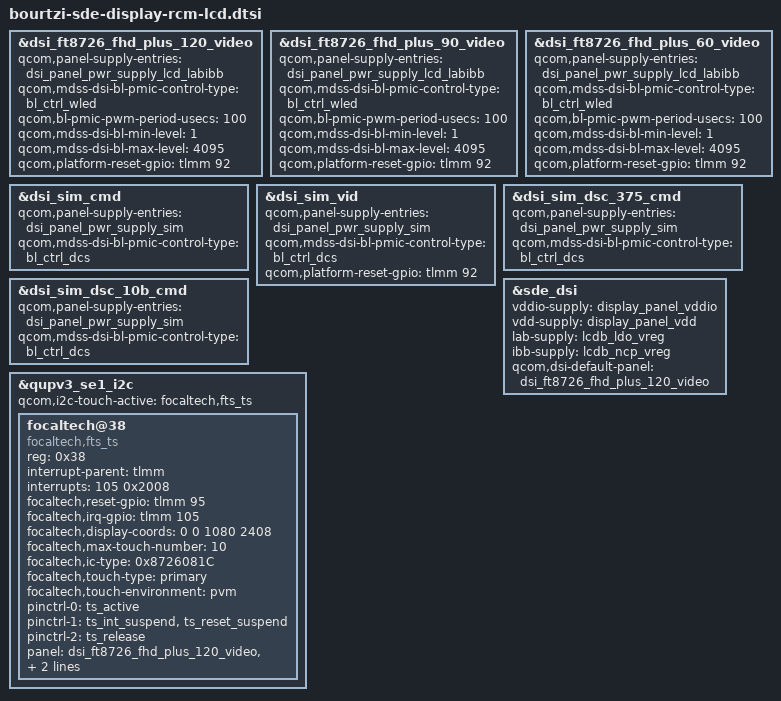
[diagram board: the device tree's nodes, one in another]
// SPDX-License-Identifier: BSD-3-Clause
/*
 * Copyright (c) Qualcomm Technologies, Inc. and/or its subsidiaries.
 */

#include "bourtzi-sde-display.dtsi"

&dsi_ft8726_fhd_plus_120_video {
	qcom,panel-supply-entries = <&dsi_panel_pwr_supply_lcd_labibb>;
	qcom,mdss-dsi-bl-pmic-control-type = "bl_ctrl_wled";
	qcom,bl-pmic-pwm-period-usecs = <100>;
	qcom,mdss-dsi-bl-min-level = <1>;
	qcom,mdss-dsi-bl-max-level = <4095>;
	qcom,platform-reset-gpio = <&tlmm 92 0>;
};

&dsi_ft8726_fhd_plus_90_video {
	qcom,panel-supply-entries = <&dsi_panel_pwr_supply_lcd_labibb>;
	qcom,mdss-dsi-bl-pmic-control-type = "bl_ctrl_wled";
	qcom,bl-pmic-pwm-period-usecs = <100>;
	qcom,mdss-dsi-bl-min-level = <1>;
	qcom,mdss-dsi-bl-max-level = <4095>;
	qcom,platform-reset-gpio = <&tlmm 92 0>;
};

&dsi_ft8726_fhd_plus_60_video {
	qcom,panel-supply-entries = <&dsi_panel_pwr_supply_lcd_labibb>;
	qcom,mdss-dsi-bl-pmic-control-type = "bl_ctrl_wled";
	qcom,bl-pmic-pwm-period-usecs = <100>;
	qcom,mdss-dsi-bl-min-level = <1>;
	qcom,mdss-dsi-bl-max-level = <4095>;
	qcom,platform-reset-gpio = <&tlmm 92 0>;
};

&dsi_sim_cmd {
	qcom,panel-supply-entries = <&dsi_panel_pwr_supply_sim>;
	qcom,mdss-dsi-bl-pmic-control-type = "bl_ctrl_dcs";
};

&dsi_sim_vid {
	qcom,panel-supply-entries = <&dsi_panel_pwr_supply_sim>;
	qcom,mdss-dsi-bl-pmic-control-type = "bl_ctrl_dcs";
	qcom,platform-reset-gpio = <&tlmm 92 0>;
};

&dsi_sim_dsc_375_cmd {
	qcom,panel-supply-entries = <&dsi_panel_pwr_supply_sim>;
	qcom,mdss-dsi-bl-pmic-control-type = "bl_ctrl_dcs";
};

&dsi_sim_dsc_10b_cmd {
	qcom,panel-supply-entries = <&dsi_panel_pwr_supply_sim>;
	qcom,mdss-dsi-bl-pmic-control-type = "bl_ctrl_dcs";
};

&sde_dsi {

	vddio-supply = <&display_panel_vddio>;
	vdd-supply = <&display_panel_vdd>;
	lab-supply = <&lcdb_ldo_vreg>;
	ibb-supply = <&lcdb_ncp_vreg>;

	qcom,dsi-default-panel = <&dsi_ft8726_fhd_plus_120_video>;
};

&qupv3_se1_i2c {
	#address-cells = <1>;
	#size-cells = <0>;

	status = "ok";
	qcom,i2c-touch-active = "focaltech,fts_ts";

	focaltech@38 {
		compatible = "focaltech,fts_ts";
		status = "ok";
		reg = <0x38>;

		interrupt-parent = <&tlmm>;
		interrupts = <105 0x2008>;
		focaltech,reset-gpio = <&tlmm 95 0x00>;
		focaltech,irq-gpio = <&tlmm 105 0x2008>;
		focaltech,display-coords = <0 0 1080 2408>;
		focaltech,max-touch-number = <10>;
		focaltech,ic-type = <0x8726081C>;
		focaltech,touch-type = "primary";
		focaltech,touch-environment = "pvm";

		pinctrl-names = "pmx_ts_active","pmx_ts_suspend","pmx_ts_release";
		pinctrl-0 = <&ts_active>;
		pinctrl-1 = <&ts_int_suspend &ts_reset_suspend>;
		pinctrl-2 = <&ts_release>;
		panel = <&dsi_ft8726_fhd_plus_120_video
			&dsi_ft8726_fhd_plus_90_video
			&dsi_ft8726_fhd_plus_60_video>;
	};
};
